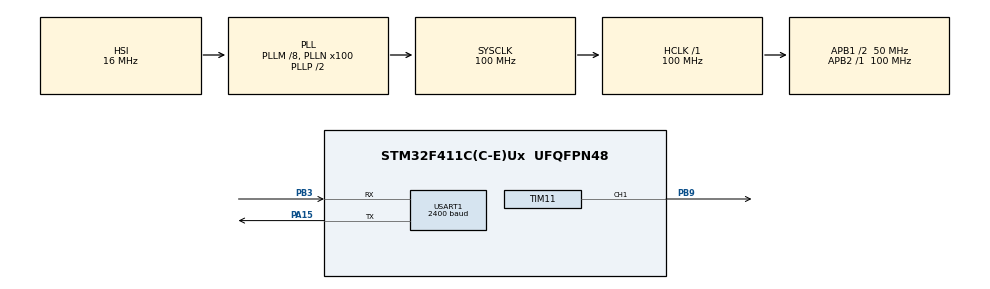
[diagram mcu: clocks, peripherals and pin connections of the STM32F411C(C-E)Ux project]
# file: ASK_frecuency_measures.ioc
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Mcu.Family=STM32F4
Mcu.Name=STM32F411C(C-E)Ux
Mcu.Package=UFQFPN48
NVIC.PriorityGroup=NVIC_PRIORITYGROUP_4
PA13.Mode=Serial_Wire
PA13.Signal=SYS_JTMS-SWDIO
PA14.Mode=Serial_Wire
PA14.Signal=SYS_JTCK-SWCLK
PA15.Mode=Asynchronous
PA15.Signal=USART1_TX
PB3.Mode=Asynchronous
PB3.Signal=USART1_RX
PB9.GPIO_PuPd=GPIO_NOPULL
PB9.GPIO_Speed=GPIO_SPEED_FREQ_VERY_HIGH
PB9.Signal=S_TIM11_CH1
PC14-OSC32_IN.Mode=LSE-External-Oscillator
PC14-OSC32_IN.Signal=RCC_OSC32_IN
PC15-OSC32_OUT.Mode=LSE-External-Oscillator
PC15-OSC32_OUT.Signal=RCC_OSC32_OUT
PH0\ -\ OSC_IN.Mode=HSE-External-Oscillator
PH0\ -\ OSC_IN.Signal=RCC_OSC_IN
PH1\ -\ OSC_OUT.Mode=HSE-External-Oscillator
PH1\ -\ OSC_OUT.Signal=RCC_OSC_OUT
ProjectManager.HeapSize=0x200
ProjectManager.StackSize=0x400
ProjectManager.TargetToolchain=STM32CubeIDE
RCC.48MHZClocksFreq_Value=50000000
RCC.AHBFreq_Value=100000000
RCC.APB1CLKDivider=RCC_HCLK_DIV2
RCC.APB1Freq_Value=50000000
RCC.APB1TimFreq_Value=100000000
RCC.APB2Freq_Value=100000000
RCC.APB2TimFreq_Value=100000000
RCC.CortexFreq_Value=100000000
RCC.HCLKFreq_Value=100000000
RCC.HSE_VALUE=25000000
RCC.HSI_VALUE=16000000
RCC.PLLM=8
RCC.PLLN=100
RCC.SYSCLKFreq_VALUE=100000000
RCC.SYSCLKSource=RCC_SYSCLKSOURCE_PLLCLK
RCC.VCOOutputFreq_Value=200000000
SH.S_TIM11_CH1.0=TIM11_CH1,PWM Generation1 CH1
TIM11.AutoReloadPreload=TIM_AUTORELOAD_PRELOAD_ENABLE
TIM11.Channel=TIM_CHANNEL_1
TIM11.OC1Preload_PWM=DISABLE
TIM11.OCFastMode_PWM=TIM_OCFAST_ENABLE
TIM11.Period=669
TIM11.Prescaler=0
USART1.BaudRate=2400
USART1.VirtualMode=VM_ASYNC
VP_TIM11_VS_ClockSourceINT.Mode=Enable_Timer
board=custom

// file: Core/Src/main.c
/* USER CODE BEGIN Header */
/**
  ******************************************************************************
  * @file           : main.c
  * @brief          : Main program body
  ******************************************************************************
  * @attention
  *
  * Copyright (c) 2024 STMicroelectronics.
  * All rights reserved.
  *
  * This software is licensed under terms that can be found in the LICENSE file
  * in the root directory of this software component.
  * If no LICENSE file comes with this software, it is provided AS-IS.
  *
  ******************************************************************************
  */
/* USER CODE END Header */
#include "main.h"

TIM_HandleTypeDef htim11;

UART_HandleTypeDef huart1;

void SystemClock_Config(void);
static void MX_GPIO_Init(void);
static void MX_USART1_UART_Init(void);
static void MX_TIM11_Init(void);

int main(void)
{

  /* MCU Configuration--------------------------------------------------------*/

  /* Reset of all peripherals, Initializes the Flash interface and the Systick. */
  HAL_Init();

  /* Configure the system clock */
  SystemClock_Config();

  /* Initialize all configured peripherals */
  MX_GPIO_Init();
  MX_USART1_UART_Init();
  MX_TIM11_Init();
  /* USER CODE BEGIN 2 */

  //Portadora de 150Khz
  HAL_TIM_PWM_Start(&htim11,TIM_CHANNEL_1);
  TIM11->CCR1 = 335; //50% DUTY CYCLE

  //Mensaje
  uint8_t msg[6] = "HOLA\r\n";

  /* USER CODE END 2 */

  /* Infinite loop */
  while (1)
  {

    /* USER CODE BEGIN 3 */
	  HAL_UART_Transmit(&huart1,msg,6,1);
	  HAL_Delay(1000);
  }
  /* USER CODE END 3 */
}

void SystemClock_Config(void)
{
  RCC_OscInitTypeDef RCC_OscInitStruct = {0};
  RCC_ClkInitTypeDef RCC_ClkInitStruct = {0};

  /** Configure the main internal regulator output voltage
  */
  __HAL_RCC_PWR_CLK_ENABLE();
  __HAL_PWR_VOLTAGESCALING_CONFIG(PWR_REGULATOR_VOLTAGE_SCALE1);

  /** Initializes the RCC Oscillators according to the specified parameters
  * in the RCC_OscInitTypeDef structure.
  */
  RCC_OscInitStruct.OscillatorType = RCC_OSCILLATORTYPE_HSI;
  RCC_OscInitStruct.HSIState = RCC_HSI_ON;
  RCC_OscInitStruct.HSICalibrationValue = RCC_HSICALIBRATION_DEFAULT;
  RCC_OscInitStruct.PLL.PLLState = RCC_PLL_ON;
  RCC_OscInitStruct.PLL.PLLSource = RCC_PLLSOURCE_HSI;
  RCC_OscInitStruct.PLL.PLLM = 8;
  RCC_OscInitStruct.PLL.PLLN = 100;
  RCC_OscInitStruct.PLL.PLLP = RCC_PLLP_DIV2;
  RCC_OscInitStruct.PLL.PLLQ = 4;
  if (HAL_RCC_OscConfig(&RCC_OscInitStruct) != HAL_OK)
  {
    Error_Handler();
  }

  /** Initializes the CPU, AHB and APB buses clocks
  */
  RCC_ClkInitStruct.ClockType = RCC_CLOCKTYPE_HCLK|RCC_CLOCKTYPE_SYSCLK
                              |RCC_CLOCKTYPE_PCLK1|RCC_CLOCKTYPE_PCLK2;
  RCC_ClkInitStruct.SYSCLKSource = RCC_SYSCLKSOURCE_PLLCLK;
  RCC_ClkInitStruct.AHBCLKDivider = RCC_SYSCLK_DIV1;
  RCC_ClkInitStruct.APB1CLKDivider = RCC_HCLK_DIV2;
  RCC_ClkInitStruct.APB2CLKDivider = RCC_HCLK_DIV1;

  if (HAL_RCC_ClockConfig(&RCC_ClkInitStruct, FLASH_LATENCY_3) != HAL_OK)
  {
    Error_Handler();
  }
}

static void MX_TIM11_Init(void)
{

  TIM_OC_InitTypeDef sConfigOC = {0};

  htim11.Instance = TIM11;
  htim11.Init.Prescaler = 0;
  htim11.Init.CounterMode = TIM_COUNTERMODE_UP;
  htim11.Init.Period = 669;
  htim11.Init.ClockDivision = TIM_CLOCKDIVISION_DIV1;
  htim11.Init.AutoReloadPreload = TIM_AUTORELOAD_PRELOAD_ENABLE;
  if (HAL_TIM_Base_Init(&htim11) != HAL_OK)
  {
    Error_Handler();
  }
  if (HAL_TIM_PWM_Init(&htim11) != HAL_OK)
  {
    Error_Handler();
  }
  sConfigOC.OCMode = TIM_OCMODE_PWM1;
  sConfigOC.Pulse = 0;
  sConfigOC.OCPolarity = TIM_OCPOLARITY_HIGH;
  sConfigOC.OCFastMode = TIM_OCFAST_ENABLE;
  if (HAL_TIM_PWM_ConfigChannel(&htim11, &sConfigOC, TIM_CHANNEL_1) != HAL_OK)
  {
    Error_Handler();
  }
  __HAL_TIM_DISABLE_OCxPRELOAD(&htim11, TIM_CHANNEL_1);
  HAL_TIM_MspPostInit(&htim11);

}

static void MX_USART1_UART_Init(void)
{

  huart1.Instance = USART1;
  huart1.Init.BaudRate = 2400;
  huart1.Init.WordLength = UART_WORDLENGTH_8B;
  huart1.Init.StopBits = UART_STOPBITS_1;
  huart1.Init.Parity = UART_PARITY_NONE;
  huart1.Init.Mode = UART_MODE_TX_RX;
  huart1.Init.HwFlowCtl = UART_HWCONTROL_NONE;
  huart1.Init.OverSampling = UART_OVERSAMPLING_16;
  if (HAL_UART_Init(&huart1) != HAL_OK)
  {
    Error_Handler();
  }

}

static void MX_GPIO_Init(void)
{

  /* GPIO Ports Clock Enable */
  __HAL_RCC_GPIOC_CLK_ENABLE();
  __HAL_RCC_GPIOH_CLK_ENABLE();
  __HAL_RCC_GPIOA_CLK_ENABLE();
  __HAL_RCC_GPIOB_CLK_ENABLE();

}

void Error_Handler(void)
{
  __disable_irq();
  while (1)
  {
  }
}
